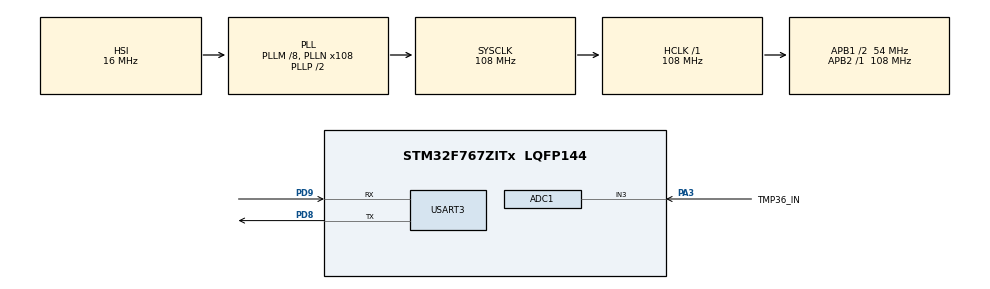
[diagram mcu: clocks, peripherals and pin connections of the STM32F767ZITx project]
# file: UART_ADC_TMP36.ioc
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ADC1.Channel-0\#ChannelRegularConversion=ADC_CHANNEL_3
ADC1.NbrOfConversionFlag=1
ADC1.Rank-0\#ChannelRegularConversion=1
ADC1.SamplingTime-0\#ChannelRegularConversion=ADC_SAMPLETIME_3CYCLES
ADC1.master=1
Mcu.Family=STM32F7
Mcu.Name=STM32F767ZITx
Mcu.Package=LQFP144
NVIC.PriorityGroup=NVIC_PRIORITYGROUP_4
PA3.GPIO_Label=TMP36_IN
PA3.Signal=ADCx_IN3
PD8.Mode=Asynchronous
PD8.Signal=USART3_TX
PD9.Mode=Asynchronous
PD9.Signal=USART3_RX
PH0/OSC_IN.Mode=HSE-External-Oscillator
PH0/OSC_IN.Signal=RCC_OSC_IN
PH1/OSC_OUT.Mode=HSE-External-Oscillator
PH1/OSC_OUT.Signal=RCC_OSC_OUT
ProjectManager.HeapSize=0x200
ProjectManager.StackSize=0x400
ProjectManager.TargetToolchain=STM32CubeIDE
RCC.AHBFreq_Value=108000000
RCC.APB1CLKDivider=RCC_HCLK_DIV2
RCC.APB1Freq_Value=54000000
RCC.APB1TimFreq_Value=108000000
RCC.APB2Freq_Value=108000000
RCC.APB2TimFreq_Value=108000000
RCC.CortexFreq_Value=108000000
RCC.HCLKFreq_Value=108000000
RCC.HSE_VALUE=8000000
RCC.HSI_VALUE=16000000
RCC.LSE_VALUE=32768
RCC.PLLM=8
RCC.PLLN=108
RCC.SYSCLKFreq_VALUE=108000000
RCC.SYSCLKSource=RCC_SYSCLKSOURCE_PLLCLK
RCC.USBFreq_Value=108000000
RCC.VCOOutputFreq_Value=216000000
SH.ADCx_IN3.0=ADC1_IN3,IN3
USART3.VirtualMode-Asynchronous=VM_ASYNC
board=custom

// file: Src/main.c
/* USER CODE BEGIN Header */
/**
  ******************************************************************************
  * @file           : main.c
  * @brief          : Main program body
  ******************************************************************************
  * @attention
  *
  * Copyright (c) 2025 STMicroelectronics.
  * All rights reserved.
  *
  * This software is licensed under terms that can be found in the LICENSE file
  * in the root directory of this software component.
  * If no LICENSE file comes with this software, it is provided AS-IS.
  *
  ******************************************************************************
  */
/* USER CODE END Header */
#include "main.h"

/* USER CODE BEGIN Includes */
#include <stdio.h>
#include <string.h>
/* USER CODE END Includes */

ADC_HandleTypeDef hadc1;

UART_HandleTypeDef huart3;

/* USER CODE BEGIN PV */
char msg[100];
uint32_t sensorVal = 0;
float sensorVolt = 0.0f;
float temperature = 0.0f;
/* USER CODE END PV */

void SystemClock_Config(void);
static void MX_GPIO_Init(void);
static void MX_ADC1_Init(void);
static void MX_USART3_UART_Init(void);

int main(void)
{

  /* MCU Configuration--------------------------------------------------------*/

  /* Reset of all peripherals, Initializes the Flash interface and the Systick. */
  HAL_Init();

  /* Configure the system clock */
  SystemClock_Config();

  /* Initialize all configured peripherals */
  MX_GPIO_Init();
  MX_ADC1_Init();
  MX_USART3_UART_Init();
  /* USER CODE BEGIN 2 */
  HAL_ADC_Stop(&hadc1);
  /* USER CODE END 2 */

  /* Infinite loop */
  while (1)
  {

  }
}

void SystemClock_Config(void)
{
  RCC_OscInitTypeDef RCC_OscInitStruct = {0};
  RCC_ClkInitTypeDef RCC_ClkInitStruct = {0};

  /** Configure the main internal regulator output voltage
  */
  __HAL_RCC_PWR_CLK_ENABLE();
  __HAL_PWR_VOLTAGESCALING_CONFIG(PWR_REGULATOR_VOLTAGE_SCALE3);

  /** Initializes the RCC Oscillators according to the specified parameters
  * in the RCC_OscInitTypeDef structure.
  */
  RCC_OscInitStruct.OscillatorType = RCC_OSCILLATORTYPE_HSI;
  RCC_OscInitStruct.HSIState = RCC_HSI_ON;
  RCC_OscInitStruct.HSICalibrationValue = RCC_HSICALIBRATION_DEFAULT;
  RCC_OscInitStruct.PLL.PLLState = RCC_PLL_ON;
  RCC_OscInitStruct.PLL.PLLSource = RCC_PLLSOURCE_HSI;
  RCC_OscInitStruct.PLL.PLLM = 8;
  RCC_OscInitStruct.PLL.PLLN = 108;
  RCC_OscInitStruct.PLL.PLLP = RCC_PLLP_DIV2;
  RCC_OscInitStruct.PLL.PLLQ = 2;
  RCC_OscInitStruct.PLL.PLLR = 2;
  if (HAL_RCC_OscConfig(&RCC_OscInitStruct) != HAL_OK)
  {
    Error_Handler();
  }

  /** Activate the Over-Drive mode
  */
  if (HAL_PWREx_EnableOverDrive() != HAL_OK)
  {
    Error_Handler();
  }

  /** Initializes the CPU, AHB and APB buses clocks
  */
  RCC_ClkInitStruct.ClockType = RCC_CLOCKTYPE_HCLK|RCC_CLOCKTYPE_SYSCLK
                              |RCC_CLOCKTYPE_PCLK1|RCC_CLOCKTYPE_PCLK2;
  RCC_ClkInitStruct.SYSCLKSource = RCC_SYSCLKSOURCE_PLLCLK;
  RCC_ClkInitStruct.AHBCLKDivider = RCC_SYSCLK_DIV1;
  RCC_ClkInitStruct.APB1CLKDivider = RCC_HCLK_DIV2;
  RCC_ClkInitStruct.APB2CLKDivider = RCC_HCLK_DIV1;

  if (HAL_RCC_ClockConfig(&RCC_ClkInitStruct, FLASH_LATENCY_3) != HAL_OK)
  {
    Error_Handler();
  }
}

static void MX_ADC1_Init(void)
{

  ADC_ChannelConfTypeDef sConfig = {0};

  /** Configure the global features of the ADC (Clock, Resolution, Data Alignment and number of conversion)
  */
  hadc1.Instance = ADC1;
  hadc1.Init.ClockPrescaler = ADC_CLOCK_SYNC_PCLK_DIV4;
  hadc1.Init.Resolution = ADC_RESOLUTION_12B;
  hadc1.Init.ScanConvMode = ADC_SCAN_DISABLE;
  hadc1.Init.ContinuousConvMode = DISABLE;
  hadc1.Init.DiscontinuousConvMode = DISABLE;
  hadc1.Init.ExternalTrigConvEdge = ADC_EXTERNALTRIGCONVEDGE_NONE;
  hadc1.Init.ExternalTrigConv = ADC_SOFTWARE_START;
  hadc1.Init.DataAlign = ADC_DATAALIGN_RIGHT;
  hadc1.Init.NbrOfConversion = 1;
  hadc1.Init.DMAContinuousRequests = DISABLE;
  hadc1.Init.EOCSelection = ADC_EOC_SINGLE_CONV;
  if (HAL_ADC_Init(&hadc1) != HAL_OK)
  {
    Error_Handler();
  }

  /** Configure for the selected ADC regular channel its corresponding rank in the sequencer and its sample time.
  */
  sConfig.Channel = ADC_CHANNEL_3;
  sConfig.Rank = ADC_REGULAR_RANK_1;
  sConfig.SamplingTime = ADC_SAMPLETIME_3CYCLES;
  if (HAL_ADC_ConfigChannel(&hadc1, &sConfig) != HAL_OK)
  {
    Error_Handler();
  }

}

static void MX_USART3_UART_Init(void)
{

  huart3.Instance = USART3;
  huart3.Init.BaudRate = 115200;
  huart3.Init.WordLength = UART_WORDLENGTH_8B;
  huart3.Init.StopBits = UART_STOPBITS_1;
  huart3.Init.Parity = UART_PARITY_NONE;
  huart3.Init.Mode = UART_MODE_TX_RX;
  huart3.Init.HwFlowCtl = UART_HWCONTROL_NONE;
  huart3.Init.OverSampling = UART_OVERSAMPLING_16;
  huart3.Init.OneBitSampling = UART_ONE_BIT_SAMPLE_DISABLE;
  huart3.AdvancedInit.AdvFeatureInit = UART_ADVFEATURE_NO_INIT;
  if (HAL_UART_Init(&huart3) != HAL_OK)
  {
    Error_Handler();
  }

}

static void MX_GPIO_Init(void)
{

  /* GPIO Ports Clock Enable */
  __HAL_RCC_GPIOH_CLK_ENABLE();
  __HAL_RCC_GPIOA_CLK_ENABLE();
  __HAL_RCC_GPIOD_CLK_ENABLE();

}

void Error_Handler(void)
{
  __disable_irq();
  while (1)
  {
  }
}
